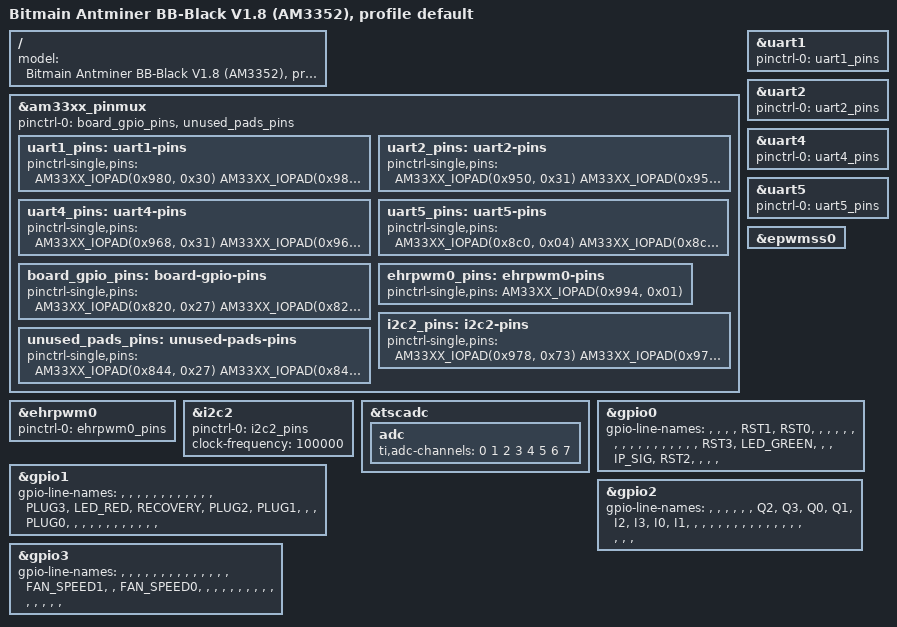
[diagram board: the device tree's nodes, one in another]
// SPDX-License-Identifier: GPL-2.0-only
/* GENERATED by pinmux/gen-dts.py from default.yaml - do not edit, edit the YAML. */
/dts-v1/;

#include "am335x-antminer-base.dtsi"

/ {
	model = "Bitmain Antminer BB-Black V1.8 (AM3352), profile default";
};

/*
 * Pin map:
 *   0x980 = 0x30  P9.26 uart1_rxd -> uart1_rxd
 *   0x984 = 0x00  P9.24 uart1_txd -> uart1_txd
 *   0x950 = 0x31  P9.22 spi0_sclk -> uart2_rxd
 *   0x954 = 0x01  P9.21 spi0_d0 -> uart2_txd
 *   0x968 = 0x31  uart0_ctsn uart0_ctsn -> uart4_rxd
 *   0x96c = 0x01  uart0_rtsn uart0_rtsn -> uart4_txd
 *   0x8c0 = 0x04  P8.37 lcd_data8 -> uart5_txd
 *   0x8c4 = 0x34  P8.38 lcd_data9 -> uart5_rxd
 *   0x820 = 0x27  P8.19 gpmc_ad8 gpio0_22 RST3 out
 *   0x824 = 0x27  P8.13 gpmc_ad9 gpio0_23 LED_GREEN out
 *   0x828 = 0x37  P8.14 gpmc_ad10 gpio0_26 IP_SIG in
 *   0x82c = 0x27  P8.17 gpmc_ad11 gpio0_27 RST2 out
 *   0x830 = 0x27  P8.12 gpmc_ad12 gpio1_12 PLUG3 in
 *   0x834 = 0x27  P8.11 gpmc_ad13 gpio1_13 LED_RED out
 *   0x838 = 0x37  P8.16 gpmc_ad14 gpio1_14 RECOVERY in
 *   0x83c = 0x27  P8.15 gpmc_ad15 gpio1_15 PLUG2 in
 *   0x840 = 0x27  P9.15 gpmc_a0 gpio1_16 PLUG1 in
 *   0x84c = 0x27  P9.16 gpmc_a3 gpio1_19 PLUG0 in
 *   0x8a0 = 0x27  P8.45 lcd_data0 gpio2_6 Q2 out
 *   0x8a4 = 0x27  P8.46 lcd_data1 gpio2_7 Q3 out
 *   0x8a8 = 0x27  P8.43 lcd_data2 gpio2_8 Q0 out
 *   0x8ac = 0x27  P8.44 lcd_data3 gpio2_9 Q1 out
 *   0x8b0 = 0x37  P8.41 lcd_data4 gpio2_10 I2 in
 *   0x8b4 = 0x37  P8.42 lcd_data5 gpio2_11 I3 in
 *   0x8b8 = 0x37  P8.39 lcd_data6 gpio2_12 I0 in
 *   0x8bc = 0x37  P8.40 lcd_data7 gpio2_13 I1 in
 *   0x958 = 0x27  P9.18 spi0_d1 gpio0_4 RST1 out
 *   0x95c = 0x27  P9.17 spi0_cs0 gpio0_5 RST0 out
 *   0x990 = 0x27  P9.31 mcasp0_aclkx gpio3_14 FAN_SPEED1 in
 *   0x998 = 0x27  P9.30 mcasp0_axr0 gpio3_16 FAN_SPEED0 in
 *   0x994 = 0x01  P9.29 mcasp0_fsx -> ehrpwm0b
 *   0x978 = 0x73  P9.20 uart1_ctsn -> i2c2_sda
 *   0x97c = 0x73  P9.19 uart1_rtsn -> i2c2_scl
 *   + 27 unused free pads forced to GPIO input pull-down (0x27)
 */

&am33xx_pinmux {
	pinctrl-names = "default";
	pinctrl-0 = <&board_gpio_pins>, <&unused_pads_pins>;

	uart1_pins: uart1-pins {
		pinctrl-single,pins = <
			AM33XX_IOPAD(0x980, 0x30)	/* P9.26 uart1_rxd -> uart1_rxd */
			AM33XX_IOPAD(0x984, 0x00)	/* P9.24 uart1_txd -> uart1_txd */
		>;
	};

	uart2_pins: uart2-pins {
		pinctrl-single,pins = <
			AM33XX_IOPAD(0x950, 0x31)	/* P9.22 spi0_sclk -> uart2_rxd */
			AM33XX_IOPAD(0x954, 0x01)	/* P9.21 spi0_d0 -> uart2_txd */
		>;
	};

	uart4_pins: uart4-pins {
		pinctrl-single,pins = <
			AM33XX_IOPAD(0x968, 0x31)	/* uart0_ctsn uart0_ctsn -> uart4_rxd */
			AM33XX_IOPAD(0x96c, 0x01)	/* uart0_rtsn uart0_rtsn -> uart4_txd */
		>;
	};

	uart5_pins: uart5-pins {
		pinctrl-single,pins = <
			AM33XX_IOPAD(0x8c0, 0x04)	/* P8.37 lcd_data8 -> uart5_txd */
			AM33XX_IOPAD(0x8c4, 0x34)	/* P8.38 lcd_data9 -> uart5_rxd */
		>;
	};

	board_gpio_pins: board-gpio-pins {
		pinctrl-single,pins = <
			AM33XX_IOPAD(0x820, 0x27)	/* P8.19 gpmc_ad8 gpio0_22 RST3 out */
			AM33XX_IOPAD(0x824, 0x27)	/* P8.13 gpmc_ad9 gpio0_23 LED_GREEN out */
			AM33XX_IOPAD(0x828, 0x37)	/* P8.14 gpmc_ad10 gpio0_26 IP_SIG in */
			AM33XX_IOPAD(0x82c, 0x27)	/* P8.17 gpmc_ad11 gpio0_27 RST2 out */
			AM33XX_IOPAD(0x830, 0x27)	/* P8.12 gpmc_ad12 gpio1_12 PLUG3 in */
			AM33XX_IOPAD(0x834, 0x27)	/* P8.11 gpmc_ad13 gpio1_13 LED_RED out */
			AM33XX_IOPAD(0x838, 0x37)	/* P8.16 gpmc_ad14 gpio1_14 RECOVERY in */
			AM33XX_IOPAD(0x83c, 0x27)	/* P8.15 gpmc_ad15 gpio1_15 PLUG2 in */
			AM33XX_IOPAD(0x840, 0x27)	/* P9.15 gpmc_a0 gpio1_16 PLUG1 in */
			AM33XX_IOPAD(0x84c, 0x27)	/* P9.16 gpmc_a3 gpio1_19 PLUG0 in */
			AM33XX_IOPAD(0x8a0, 0x27)	/* P8.45 lcd_data0 gpio2_6 Q2 out */
			AM33XX_IOPAD(0x8a4, 0x27)	/* P8.46 lcd_data1 gpio2_7 Q3 out */
			AM33XX_IOPAD(0x8a8, 0x27)	/* P8.43 lcd_data2 gpio2_8 Q0 out */
			AM33XX_IOPAD(0x8ac, 0x27)	/* P8.44 lcd_data3 gpio2_9 Q1 out */
			AM33XX_IOPAD(0x8b0, 0x37)	/* P8.41 lcd_data4 gpio2_10 I2 in */
			AM33XX_IOPAD(0x8b4, 0x37)	/* P8.42 lcd_data5 gpio2_11 I3 in */
			AM33XX_IOPAD(0x8b8, 0x37)	/* P8.39 lcd_data6 gpio2_12 I0 in */
			AM33XX_IOPAD(0x8bc, 0x37)	/* P8.40 lcd_data7 gpio2_13 I1 in */
			AM33XX_IOPAD(0x958, 0x27)	/* P9.18 spi0_d1 gpio0_4 RST1 out */
			AM33XX_IOPAD(0x95c, 0x27)	/* P9.17 spi0_cs0 gpio0_5 RST0 out */
			AM33XX_IOPAD(0x990, 0x27)	/* P9.31 mcasp0_aclkx gpio3_14 FAN_SPEED1 in */
			AM33XX_IOPAD(0x998, 0x27)	/* P9.30 mcasp0_axr0 gpio3_16 FAN_SPEED0 in */
		>;
	};

	ehrpwm0_pins: ehrpwm0-pins {
		pinctrl-single,pins = <
			AM33XX_IOPAD(0x994, 0x01)	/* P9.29 mcasp0_fsx -> ehrpwm0b */
		>;
	};

	i2c2_pins: i2c2-pins {
		pinctrl-single,pins = <
			AM33XX_IOPAD(0x978, 0x73)	/* P9.20 uart1_ctsn -> i2c2_sda */
			AM33XX_IOPAD(0x97c, 0x73)	/* P9.19 uart1_rtsn -> i2c2_scl */
		>;
	};

	unused_pads_pins: unused-pads-pins {
		pinctrl-single,pins = <
			AM33XX_IOPAD(0x844, 0x27)	/* P9.23 gpmc_a1 unused -> gpio in pulldown */
			AM33XX_IOPAD(0x848, 0x27)	/* P9.14 gpmc_a2 unused -> gpio in pulldown */
			AM33XX_IOPAD(0x850, 0x27)	/* gpmc_a4 gpmc_a4 unused -> gpio in pulldown */
			AM33XX_IOPAD(0x878, 0x27)	/* P9.12 gpmc_ben1 unused -> gpio in pulldown */
			AM33XX_IOPAD(0x880, 0x27)	/* P8.21 gpmc_csn1 unused -> gpio in pulldown */
			AM33XX_IOPAD(0x884, 0x27)	/* P8.20 gpmc_csn2 unused -> gpio in pulldown */
			AM33XX_IOPAD(0x88c, 0x27)	/* P8.18 gpmc_clk unused -> gpio in pulldown */
			AM33XX_IOPAD(0x8c8, 0x27)	/* P8.36 lcd_data10 unused -> gpio in pulldown */
			AM33XX_IOPAD(0x8cc, 0x27)	/* P8.34 lcd_data11 unused -> gpio in pulldown */
			AM33XX_IOPAD(0x8d0, 0x27)	/* P8.35 lcd_data12 unused -> gpio in pulldown */
			AM33XX_IOPAD(0x8d4, 0x27)	/* P8.33 lcd_data13 unused -> gpio in pulldown */
			AM33XX_IOPAD(0x8d8, 0x27)	/* P8.31 lcd_data14 unused -> gpio in pulldown */
			AM33XX_IOPAD(0x8dc, 0x27)	/* P8.32 lcd_data15 unused -> gpio in pulldown */
			AM33XX_IOPAD(0x8e0, 0x27)	/* P8.27 lcd_vsync unused -> gpio in pulldown */
			AM33XX_IOPAD(0x8e4, 0x27)	/* P8.29 lcd_hsync unused -> gpio in pulldown */
			AM33XX_IOPAD(0x8e8, 0x27)	/* P8.28 lcd_pclk unused -> gpio in pulldown */
			AM33XX_IOPAD(0x8ec, 0x27)	/* P8.30 lcd_ac_bias_en unused -> gpio in pulldown */
			AM33XX_IOPAD(0x908, 0x27)	/* mii1_col mii1_col unused -> gpio in pulldown */
			AM33XX_IOPAD(0x90c, 0x27)	/* mii1_crs mii1_crs unused -> gpio in pulldown */
			AM33XX_IOPAD(0x964, 0x27)	/* P9.42 ecap0_in_pwm0_out unused -> gpio in pulldown */
			AM33XX_IOPAD(0x99c, 0x27)	/* P9.28 mcasp0_ahclkr unused -> gpio in pulldown */
			AM33XX_IOPAD(0x9a0, 0x27)	/* mcasp0_aclkr mcasp0_aclkr unused -> gpio in pulldown */
			AM33XX_IOPAD(0x9a4, 0x27)	/* P9.27 mcasp0_fsr unused -> gpio in pulldown */
			AM33XX_IOPAD(0x9a8, 0x27)	/* mcasp0_axr1 mcasp0_axr1 unused -> gpio in pulldown */
			AM33XX_IOPAD(0x9ac, 0x27)	/* P9.25 mcasp0_ahclkx unused -> gpio in pulldown */
			AM33XX_IOPAD(0x9b0, 0x27)	/* xdma_event_intr0 xdma_event_intr0 unused -> gpio in pulldown */
			AM33XX_IOPAD(0x9b4, 0x27)	/* P9.41 xdma_event_intr1 unused -> gpio in pulldown */
		>;
	};

};

&ehrpwm0 {
	status = "okay";
	pinctrl-names = "default";
	pinctrl-0 = <&ehrpwm0_pins>;
};

&i2c2 {
	status = "okay";
	pinctrl-names = "default";
	pinctrl-0 = <&i2c2_pins>;
	clock-frequency = <100000>;
};

&uart1 {
	status = "okay";
	pinctrl-names = "default";
	pinctrl-0 = <&uart1_pins>;
};

&uart2 {
	status = "okay";
	pinctrl-names = "default";
	pinctrl-0 = <&uart2_pins>;
};

&uart4 {
	status = "okay";
	pinctrl-names = "default";
	pinctrl-0 = <&uart4_pins>;
};

&uart5 {
	status = "okay";
	pinctrl-names = "default";
	pinctrl-0 = <&uart5_pins>;
};

&epwmss0 {
	status = "okay";
};

&tscadc {
	status = "okay";
	adc {
		ti,adc-channels = <0 1 2 3 4 5 6 7>;
	};
};

&gpio0 {
	gpio-line-names =
		"", "", "", "", "RST1", "RST0", "", "",
		"", "", "", "", "", "", "", "",
		"", "", "", "", "", "", "RST3", "LED_GREEN",
		"", "", "IP_SIG", "RST2", "", "", "", "";
};

&gpio1 {
	gpio-line-names =
		"", "", "", "", "", "", "", "",
		"", "", "", "", "PLUG3", "LED_RED", "RECOVERY", "PLUG2",
		"PLUG1", "", "", "PLUG0", "", "", "", "",
		"", "", "", "", "", "", "", "";
};

&gpio2 {
	gpio-line-names =
		"", "", "", "", "", "", "Q2", "Q3",
		"Q0", "Q1", "I2", "I3", "I0", "I1", "", "",
		"", "", "", "", "", "", "", "",
		"", "", "", "", "", "", "", "";
};

&gpio3 {
	gpio-line-names =
		"", "", "", "", "", "", "", "",
		"", "", "", "", "", "", "FAN_SPEED1", "",
		"FAN_SPEED0", "", "", "", "", "", "", "",
		"", "", "", "", "", "", "", "";
};

